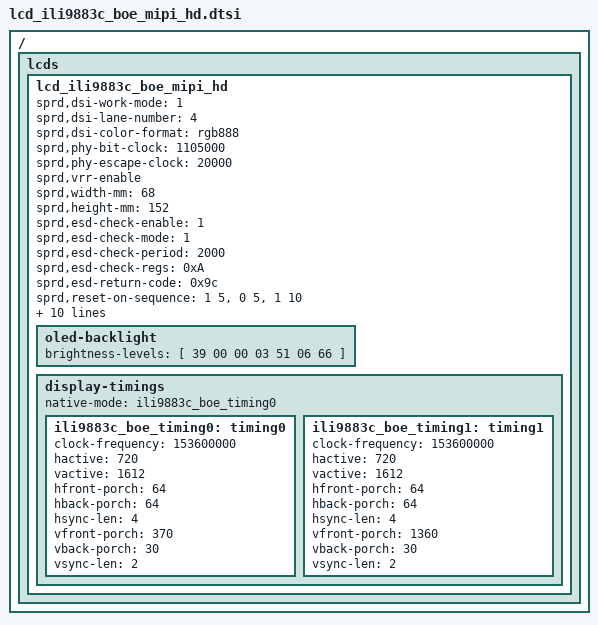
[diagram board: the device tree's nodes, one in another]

/*
 * ili9883c LCD config dtsi file for spreadtrum
 *
 * Copyright (C) 2022, Spreadtrum Communications Inc.
 *
 * SPDX-License-Identifier: (GPL-2.0+ OR MIT)
 */

/ {
	fragment {
		target-path = "/";
		__overlay__ {
			lcds {
				lcd_ili9883c_boe_mipi_hd: lcd_ili9883c_boe_mipi_hd {

					sprd,dsi-work-mode = <1>; /* video burst mode*/
					sprd,dsi-lane-number = <4>;
					sprd,dsi-color-format = "rgb888";

					sprd,phy-bit-clock = <1105000>;	/* kbps */
					sprd,phy-escape-clock = <20000>;/* kHz */
					sprd,vrr-enable;  /*90hz 60hz*/
					//sprd,power-gpio-delay = <20>; ms
					sprd,width-mm = <68>;
					sprd,height-mm = <152>;
					//sprd,dpi-clk-div = <6>;
					//sprd,video-lp-cmd-enable = <1>;
					//sprd,hporch-lp-disable = <1>;
					sprd,esd-check-enable = <1>;
					sprd,esd-check-mode = <1>;
					sprd,esd-check-period = <2000>;
					sprd,esd-check-regs = <0xA>;
					sprd,esd-return-code = <0x9c>;

					sprd,reset-on-sequence = <1 5>, <0 5>, <1 10>;
					//sprd,reset-off-sequence = <0 5>;

					sprd,initial-command = [
						39 00 00 04 FF 98 83 03
						15 00 00 02 81 06
						15 00 00 02 83 B8
						15 00 00 02 84 02
						15 00 00 02 8C E3
						15 00 00 02 8D E6
						15 00 00 02 8E EF
						15 00 00 02 8F F0
						15 00 00 02 90 F3
						15 00 00 02 91 F5
						15 00 00 02 92 F7
						15 00 00 02 93 F9
						15 00 00 02 94 FA
						15 00 00 02 95 FF
						15 00 00 02 96 B5
						15 00 00 02 97 BA
						15 00 00 02 98 BF
						15 00 00 02 99 C4
						15 00 00 02 9A C9
						15 00 00 02 9B CD
						15 00 00 02 9C D5
						15 00 00 02 9D E6
						15 00 00 02 9E F6
						15 00 00 02 9F FB
						15 00 00 02 87 4D
						15 00 00 02 AD FF
						15 00 00 02 B4 FF
						39 00 00 04 FF 98 83 06
						15 00 00 02 06 A4
						39 00 00 04 FF 98 83 00
						39 00 00 03 51 00 00
						39 00 00 03 68 04 01
						15 00 00 02 53 2C
						15 00 00 02 55 02
						15 00 00 02 35 00
						05 78 00 01 11
						05 14 00 01 29
						];

					sprd,sleep-in-command = [
						39 0A 00 01 28
						39 78 00 01 10
						];

					sprd,sleep-out-command = [
						39 78 00 01 11
						39 14 00 01 29
						];

					sprd,cabc-on-command = [
						39 00 00 04 FF 98 83 00
						39 00 00 02 55 02
						];

					sprd,cabc-off-command = [
						39 00 00 04 FF 98 83 00
						39 00 00 02 55 00
						];

					oled-backlight {
						//default-brightness = <900>;
						//sprd,max-level = <4095>;
						brightness-levels = [
						39 00 00 03 51 06 66
						];
					};

					display-timings {
						native-mode = <&ili9883c_boe_timing0>;

						ili9883c_boe_timing0: timing0 {
							clock-frequency = <153600000>;
							hactive = <720>;
							vactive = <1612>;
							hfront-porch = <64>;
							hback-porch = <64>;
							hsync-len = <4>;
							vfront-porch = <370>;
							vback-porch = <30>;
							vsync-len = <2>;
						};
						ili9883c_boe_timing1: timing1 {
							clock-frequency = <153600000>;
							hactive = <720>;
							vactive = <1612>;
							hfront-porch = <64>;
							hback-porch = <64>;
							hsync-len = <4>;
							vfront-porch = <1360>;
							vback-porch = <30>;
							vsync-len = <2>;
						};
					};
				};
			};
		};
	};
};
